# mlbss_MLBSS_CFG_02F80000h register map
Vendor: Texas Instruments
Peripheral module from a debugger description file (folder AM275x).
Registers are 32-bit, read-only, reset 0x0 unless marked. A register's access mark holds for its fields unless they carry their own. Offsets are as the file gives them; lines under a group give offsets from that group; [hi:lo] are bit positions; {n}, {i} and the like mark numbered series; 'fields as' and 'values as' point back to an identical list; <NAME> marks a mode.

## mlbss_cfg
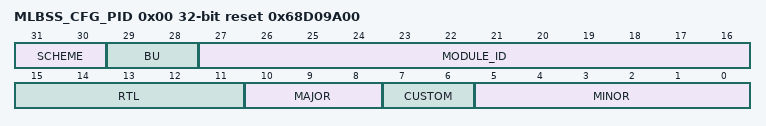
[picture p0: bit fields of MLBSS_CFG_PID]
0x00 MLBSS_CFG_PID reset 0x68D09A00 — The Revision Register contains the major and minor revisions for the module.
  [31:30] SCHEME — PID register scheme Reset Source: psrst_n
  [29:28] BU — Business Unit: 10 = Processors Reset Source: psrst_n
  [27:16] MODULE_ID — Module ID Reset Source: psrst_n
  [15:11] RTL — RTL revision. Will vary depending on release. Reset Source: psrst_n
  [10:8] MAJOR — Major revision Reset Source: psrst_n
  [7:6] CUSTOM — Custom Reset Source: psrst_n
  [5:0] MINOR — Minor revision Reset Source: psrst_n
0x08 MLBSS_CFG_STAT — The Status register provide general status bits for the mlbss
  [1] MEM_INIT_DONE — 0:Memory Initialization is in progress, 1:Memory Intialization Done Reset Source: psrst_n
0x0C MLBSS_CFG_DMA_CTRL rw — The DMA Control register provide control bits for the DMA Vbusp
  [2:0] PRIORITY — DMA Vbusp priority Reset Source: psrst_n
